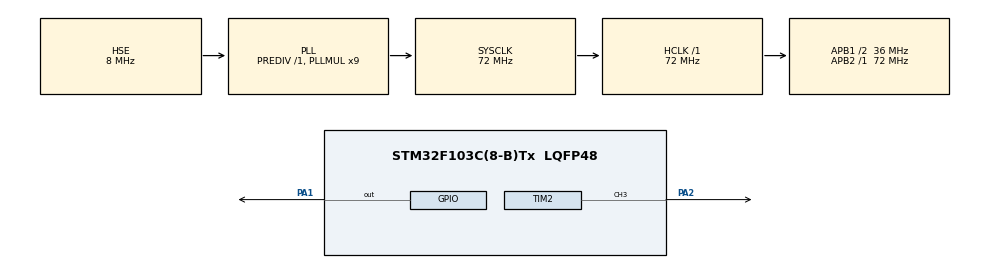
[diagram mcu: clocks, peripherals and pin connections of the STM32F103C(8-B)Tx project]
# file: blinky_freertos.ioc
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FREERTOS.HEAP_NUMBER=4
FREERTOS.INCLUDE_eTaskGetState=1
FREERTOS.INCLUDE_pcTaskGetTaskName=0
FREERTOS.INCLUDE_uxTaskGetStackHighWaterMark=1
FREERTOS.INCLUDE_uxTaskGetStackHighWaterMark2=0
FREERTOS.INCLUDE_uxTaskPriorityGet=1
FREERTOS.INCLUDE_vTaskCleanUpResources=0
FREERTOS.INCLUDE_vTaskDelay=1
FREERTOS.INCLUDE_vTaskDelayUntil=1
FREERTOS.INCLUDE_vTaskDelete=1
FREERTOS.INCLUDE_vTaskPrioritySet=1
FREERTOS.INCLUDE_vTaskSuspend=1
FREERTOS.INCLUDE_xEventGroupSetBitFromISR=0
FREERTOS.INCLUDE_xQueueGetMutexHolder=1
FREERTOS.INCLUDE_xSemaphoreGetMutexHolder=0
FREERTOS.INCLUDE_xTaskAbortDelay=0
FREERTOS.INCLUDE_xTaskGetCurrentTaskHandle=1
FREERTOS.INCLUDE_xTaskGetHandle=0
FREERTOS.INCLUDE_xTaskGetSchedulerState=1
FREERTOS.INCLUDE_xTaskResumeFromISR=1
FREERTOS.INCLUDE_xTimerPendFunctionCall=1
FREERTOS.Tasks01=defaultTask,24,128,StartDefaultTask,Default,NULL,Dynamic,NULL,NULL;blink,40,128,StartTask02,Default,NULL,Dynamic,NULL,NULL
FREERTOS.configCHECK_FOR_STACK_OVERFLOW=0
FREERTOS.configENABLE_BACKWARD_COMPATIBILITY=1
FREERTOS.configENABLE_FPU=0
FREERTOS.configGENERATE_RUN_TIME_STATS=0
FREERTOS.configIDLE_SHOULD_YIELD=1
FREERTOS.configLIBRARY_LOWEST_INTERRUPT_PRIORITY=15
FREERTOS.configLIBRARY_MAX_SYSCALL_INTERRUPT_PRIORITY=5
FREERTOS.configMAX_CO_ROUTINE_PRIORITIES=2
FREERTOS.configMAX_TASK_NAME_LEN=16
FREERTOS.configMINIMAL_STACK_SIZE=128
FREERTOS.configQUEUE_REGISTRY_SIZE=8
FREERTOS.configRECORD_STACK_HIGH_ADDRESS=0
FREERTOS.configTICK_RATE_HZ=1000
FREERTOS.configTIMER_QUEUE_LENGTH=10
FREERTOS.configTIMER_TASK_PRIORITY=2
FREERTOS.configTIMER_TASK_STACK_DEPTH=256
FREERTOS.configTOTAL_HEAP_SIZE=3072
FREERTOS.configUSE_APPLICATION_TASK_TAG=0
FREERTOS.configUSE_COUNTING_SEMAPHORES=1
FREERTOS.configUSE_CO_ROUTINES=0
FREERTOS.configUSE_DAEMON_TASK_STARTUP_HOOK=0
FREERTOS.configUSE_IDLE_HOOK=0
FREERTOS.configUSE_MALLOC_FAILED_HOOK=0
FREERTOS.configUSE_MINI_LIST_ITEM=1
FREERTOS.configUSE_MUTEXES=1
FREERTOS.configUSE_NEWLIB_REENTRANT=0
FREERTOS.configUSE_OS2_EVENTFLAGS_FROM_ISR=1
FREERTOS.configUSE_OS2_MUTEX=1
FREERTOS.configUSE_OS2_THREAD_ENUMERATE=1
FREERTOS.configUSE_OS2_THREAD_FLAGS=1
FREERTOS.configUSE_OS2_THREAD_SUSPEND_RESUME=1
FREERTOS.configUSE_OS2_TIMER=1
FREERTOS.configUSE_POSIX_ERRNO=0
FREERTOS.configUSE_PREEMPTION=1
FREERTOS.configUSE_RECURSIVE_MUTEXES=1
FREERTOS.configUSE_SB_COMPLETED_CALLBACK=0
FREERTOS.configUSE_STATS_FORMATTING_FUNCTIONS=0
FREERTOS.configUSE_TASK_NOTIFICATIONS=1
FREERTOS.configUSE_TICKLESS_IDLE=0
FREERTOS.configUSE_TICK_HOOK=0
FREERTOS.configUSE_TRACE_FACILITY=1
FREERTOS.copyHeapFile=1
Mcu.Family=STM32F1
Mcu.Name=STM32F103C(8-B)Tx
Mcu.Package=LQFP48
NVIC.PriorityGroup=NVIC_PRIORITYGROUP_4
NVIC.TIM1_UP_IRQn=true\:15\:0\:false\:false\:true\:false\:true\:true\:true
NVIC.TimeBase=TIM1_UP_IRQn
NVIC.TimeBaseIP=TIM1
PA1.Signal=GPIO_Output
PA13.Mode=Trace_Asynchronous_SW
PA13.Signal=SYS_JTMS-SWDIO
PA14.Mode=Trace_Asynchronous_SW
PA14.Signal=SYS_JTCK-SWCLK
PA2.Signal=S_TIM2_CH3
PB3.Mode=Trace_Asynchronous_SW
PB3.Signal=SYS_JTDO-TRACESWO
PD0-OSC_IN.Mode=HSE-External-Oscillator
PD0-OSC_IN.Signal=RCC_OSC_IN
PD1-OSC_OUT.Mode=HSE-External-Oscillator
PD1-OSC_OUT.Signal=RCC_OSC_OUT
ProjectManager.HeapSize=0x200
ProjectManager.StackSize=0x400
ProjectManager.TargetToolchain=CMake
RCC.AHBFreq_Value=72000000
RCC.APB1CLKDivider=RCC_HCLK_DIV2
RCC.APB1Freq_Value=36000000
RCC.APB1TimFreq_Value=72000000
RCC.APB2Freq_Value=72000000
RCC.APB2TimFreq_Value=72000000
RCC.FLatency=FLASH_LATENCY_2
RCC.HCLKFreq_Value=72000000
RCC.PLLMUL=RCC_PLL_MUL9
RCC.PLLSourceVirtual=RCC_PLLSOURCE_HSE
RCC.SYSCLKFreq_VALUE=72000000
RCC.SYSCLKSource=RCC_SYSCLKSOURCE_PLLCLK
RCC.USBFreq_Value=72000000
SH.S_TIM2_CH3.0=TIM2_CH3,PWM Generation3 CH3
TIM2.Channel-PWM\ Generation3\ CH3=TIM_CHANNEL_3
TIM2.Period=100-1
TIM2.Prescaler=72-1
TIM2.Pulse-PWM\ Generation3\ CH3=50
VP_FREERTOS_VS_CMSIS_V2.Mode=CMSIS_V2
VP_SYS_VS_tim1.Mode=TIM1
board=custom

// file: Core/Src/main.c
/* USER CODE BEGIN Header */
/**
 ******************************************************************************
 * @file           : main.c
 * @brief          : Main program body
 ******************************************************************************
 * @attention
 *
 * Copyright (c) 2026 STMicroelectronics.
 * All rights reserved.
 *
 * This software is licensed under terms that can be found in the LICENSE file
 * in the root directory of this software component.
 * If no LICENSE file comes with this software, it is provided AS-IS.
 *
 ******************************************************************************
 */
/* USER CODE END Header */
#include "main.h"
#include "cmsis_os.h"

TIM_HandleTypeDef htim2;

/* Definitions for defaultTask */
osThreadId_t defaultTaskHandle;
const osThreadAttr_t defaultTask_attributes = {
    .name = "defaultTask",
    .stack_size = 128 * 4,
    .priority = (osPriority_t)osPriorityNormal,
};
/* Definitions for blink */
osThreadId_t blinkHandle;
const osThreadAttr_t blink_attributes = {
    .name = "blink",
    .stack_size = 128 * 4,
    .priority = (osPriority_t)osPriorityHigh,
};

void SystemClock_Config(void);
static void MX_GPIO_Init(void);
static void MX_TIM2_Init(void);
void StartDefaultTask(void *argument);
void StartTask02(void *argument);

int main(void) {

  /* MCU Configuration--------------------------------------------------------*/

  /* Reset of all peripherals, Initializes the Flash interface and the Systick.
   */
  HAL_Init();

  /* Configure the system clock */
  SystemClock_Config();

  /* Initialize all configured peripherals */
  MX_GPIO_Init();
  MX_TIM2_Init();
  /* USER CODE BEGIN 2 */
  HAL_TIM_PWM_Start(&htim2, TIM_CHANNEL_3);
  /* USER CODE END 2 */

  /* Init scheduler */
  osKernelInitialize();

  /* Create the thread(s) */
  /* creation of defaultTask */
  defaultTaskHandle =
      osThreadNew(StartDefaultTask, NULL, &defaultTask_attributes);

  /* creation of blink */
  blinkHandle = osThreadNew(StartTask02, NULL, &blink_attributes);

  /* Start scheduler */
  osKernelStart();

  /* We should never get here as control is now taken by the scheduler */

  /* Infinite loop */
  while (1) {

  }
}

void SystemClock_Config(void) {
  RCC_OscInitTypeDef RCC_OscInitStruct = {0};
  RCC_ClkInitTypeDef RCC_ClkInitStruct = {0};

  /** Initializes the RCC Oscillators according to the specified parameters
   * in the RCC_OscInitTypeDef structure.
   */
  RCC_OscInitStruct.OscillatorType = RCC_OSCILLATORTYPE_HSE;
  RCC_OscInitStruct.HSEState = RCC_HSE_ON;
  RCC_OscInitStruct.HSEPredivValue = RCC_HSE_PREDIV_DIV1;
  RCC_OscInitStruct.HSIState = RCC_HSI_ON;
  RCC_OscInitStruct.PLL.PLLState = RCC_PLL_ON;
  RCC_OscInitStruct.PLL.PLLSource = RCC_PLLSOURCE_HSE;
  RCC_OscInitStruct.PLL.PLLMUL = RCC_PLL_MUL9;
  if (HAL_RCC_OscConfig(&RCC_OscInitStruct) != HAL_OK) {
    Error_Handler();
  }

  /** Initializes the CPU, AHB and APB buses clocks
   */
  RCC_ClkInitStruct.ClockType = RCC_CLOCKTYPE_HCLK | RCC_CLOCKTYPE_SYSCLK |
                                RCC_CLOCKTYPE_PCLK1 | RCC_CLOCKTYPE_PCLK2;
  RCC_ClkInitStruct.SYSCLKSource = RCC_SYSCLKSOURCE_PLLCLK;
  RCC_ClkInitStruct.AHBCLKDivider = RCC_SYSCLK_DIV1;
  RCC_ClkInitStruct.APB1CLKDivider = RCC_HCLK_DIV2;
  RCC_ClkInitStruct.APB2CLKDivider = RCC_HCLK_DIV1;

  if (HAL_RCC_ClockConfig(&RCC_ClkInitStruct, FLASH_LATENCY_2) != HAL_OK) {
    Error_Handler();
  }
}

static void MX_TIM2_Init(void) {

  TIM_MasterConfigTypeDef sMasterConfig = {0};
  TIM_OC_InitTypeDef sConfigOC = {0};

  htim2.Instance = TIM2;
  htim2.Init.Prescaler = 720 - 1;
  htim2.Init.CounterMode = TIM_COUNTERMODE_UP;
  htim2.Init.Period = 1000 - 1;
  htim2.Init.ClockDivision = TIM_CLOCKDIVISION_DIV1;
  htim2.Init.AutoReloadPreload = TIM_AUTORELOAD_PRELOAD_DISABLE;
  if (HAL_TIM_PWM_Init(&htim2) != HAL_OK) {
    Error_Handler();
  }
  sMasterConfig.MasterOutputTrigger = TIM_TRGO_RESET;
  sMasterConfig.MasterSlaveMode = TIM_MASTERSLAVEMODE_DISABLE;
  if (HAL_TIMEx_MasterConfigSynchronization(&htim2, &sMasterConfig) != HAL_OK) {
    Error_Handler();
  }
  sConfigOC.OCMode = TIM_OCMODE_PWM1;
  sConfigOC.Pulse = 500;
  sConfigOC.OCPolarity = TIM_OCPOLARITY_HIGH;
  sConfigOC.OCFastMode = TIM_OCFAST_DISABLE;
  if (HAL_TIM_PWM_ConfigChannel(&htim2, &sConfigOC, TIM_CHANNEL_3) != HAL_OK) {
    Error_Handler();
  }
  HAL_TIM_MspPostInit(&htim2);
}

static void MX_GPIO_Init(void) {
  GPIO_InitTypeDef GPIO_InitStruct = {0};

  /* GPIO Ports Clock Enable */
  __HAL_RCC_GPIOD_CLK_ENABLE();
  __HAL_RCC_GPIOA_CLK_ENABLE();
  __HAL_RCC_GPIOB_CLK_ENABLE();

  /*Configure GPIO pin Output Level */
  HAL_GPIO_WritePin(GPIOA, GPIO_PIN_1, GPIO_PIN_RESET);

  /*Configure GPIO pin : PA1 */
  GPIO_InitStruct.Pin = GPIO_PIN_1;
  GPIO_InitStruct.Mode = GPIO_MODE_OUTPUT_PP;
  GPIO_InitStruct.Pull = GPIO_NOPULL;
  GPIO_InitStruct.Speed = GPIO_SPEED_FREQ_LOW;
  HAL_GPIO_Init(GPIOA, &GPIO_InitStruct);

}

void StartDefaultTask(void *argument) {
  for (;;) {
    osDelay(1);
  }
}

void StartTask02(void *argument) {
  /* USER CODE BEGIN StartTask02 */
  /* Infinite loop */
  for (;;) {
    HAL_GPIO_WritePin(GPIOA, GPIO_PIN_1, GPIO_PIN_SET);
    osDelay(500);
    HAL_GPIO_WritePin(GPIOA, GPIO_PIN_1, GPIO_PIN_RESET);
    osDelay(500);
  }
  /* USER CODE END StartTask02 */
}

void HAL_TIM_PeriodElapsedCallback(TIM_HandleTypeDef *htim) {
  if (htim->Instance == TIM1) {
    HAL_IncTick();
  }
}

void Error_Handler(void) {
  __disable_irq();
  while (1) {
  }
}
#ifdef USE_FULL_ASSERT
/**
 * @brief  Reports the name of the source file and the source line number
 *         where the assert_param error has occurred.
 * @param  file: pointer to the source file name
 * @param  line: assert_param error line source number
 * @retval None
 */
void assert_failed(uint8_t *file, uint32_t line) {
  /* USER CODE BEGIN 6 */
  /* User can add his own implementation to report the file name and line
     number, ex: printf("Wrong parameters value: file %s on line %d\r\n", file,
     line) */
  /* USER CODE END 6 */
}
#endif /* USE_FULL_ASSERT */
